# Windsock register map
CPU: VexRiscV 2.0.0, little endian, no MPU, no FPU, 0 interrupt priority bits
Registers are 32-bit, read-write, reset 0x0 unless marked. A register's access mark holds for its fields unless they carry their own. Offsets are from the block's base; lines under a group give offsets from that group; [hi:lo] are bit positions; {n}, {i} and the like mark numbered series; 'fields as' and 'values as' point back to an identical list; <NAME> marks a mode.

## Memory map
0xF0000000 SYSTEM size 0x20 — System information and status register
0xF0010000 GPIOA size 0xC — General Purpose I/O
0xF0020000 UART1 size 0x80 — Universal synchronous asynchronous receiver/transmitter
0xF0030000 TIMER1 size 0x12

## SYSTEM — System information and status register
Base 0xF0000000
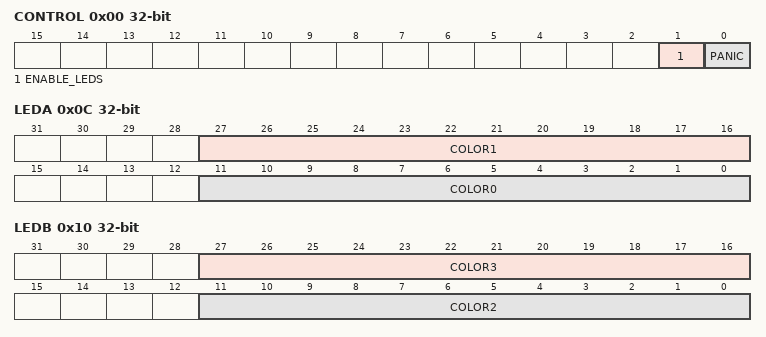
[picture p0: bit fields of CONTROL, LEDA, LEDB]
0x00 CONTROL — System reset and control register
  [1] ENABLE_LEDS — Onboard leds controler enable
  [0] PANIC — Application panic flag
0x04 CLOCK ro — System clock frequency in Hertz
0x08 PERIOD ro — System clock period in nanoseconds
0x0C LEDA — Leds colors register
  [27:16] COLOR1 — Led2 color
  [11:0] COLOR0 — Led1 color
0x10 LEDB — Leds colors register
  [27:16] COLOR3 — Led3 color
  [11:0] COLOR2 — Led2 color

## GPIOA — General Purpose I/O
Base 0xF0010000
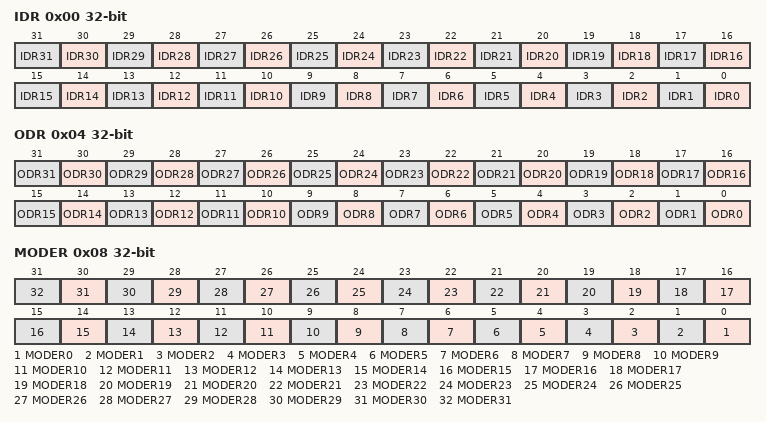
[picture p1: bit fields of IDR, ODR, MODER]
0x00 IDR ro — GPIO port input data register
  [n] IDR{n} (n=0..31) — Pin {n} input data
0x04 ODR — GPIO port output data register
  [n] ODR{n} (n=0..31) — Pin {n} output data
0x08 MODER — GPIO port mode register
  [n] MODER{n} (n=0..31) — Pin {n} mode

## UART1 — Universal synchronous asynchronous receiver/transmitter
Base 0xF0020000
0x00 DATA — UART data register
  [7:0] TX wo — TX data
  [7:0] RX ro — RX data
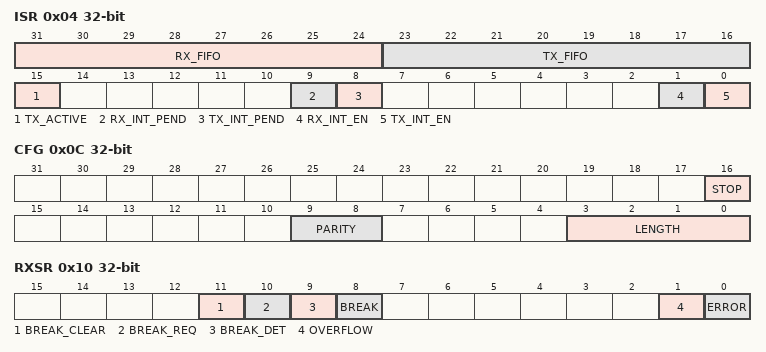
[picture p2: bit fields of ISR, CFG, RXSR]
0x04 ISR — UART interrupt status register
  [31:24] RX_FIFO ro — RX fifo occupancy
  [23:16] TX_FIFO ro — TX FIFO availability
  [15] TX_ACTIVE ro — TX active flag
  [9] RX_INT_PEND ro — RX interrupt pending flag
  [8] TX_INT_PEND ro — TX interrupt pending flag
  [1] RX_INT_EN — RX interrupt enable
  [0] TX_INT_EN — TX interrupt enable
0x08 DIV — UART clock divider register
0x0C CFG — UART frame configuration register
  [16] STOP — Stop bits
  [9:8] PARITY
  [3:0] LENGTH — Word length
0x10 RXSR — UART RX status register
  [11] BREAK_CLEAR wo — Stop bits
  [10] BREAK_REQ wo — Stop bits
  [9] BREAK_DET — Stop bits
  [8] BREAK ro — Stop bits
  [1] OVERFLOW ro — RX overflow flag
  [0] ERROR ro — RX error flag

## TIMER1
Base 0xF0030000
0x00 COUNTER — Timer counter register
0x04 PSC — Timer prescaler register
0x08 LIMIT — Timer limit register
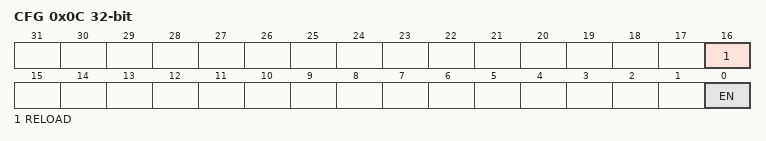
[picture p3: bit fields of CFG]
0x0C CFG — Timer configuration register
  [16] RELOAD — Timer auto reload
  [0] EN — Timer enable
0x10 SR — Status register
0x14 ISR — Timer interrupt status register
0x18 MASKR — Timer interrupt mask register
